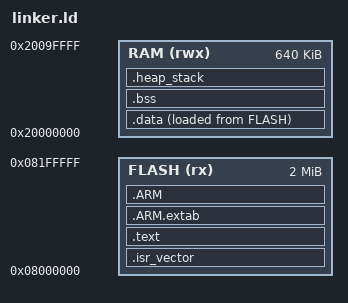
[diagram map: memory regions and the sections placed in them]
/*
 * linker.ld — STM32L4R5 linker script (rebarscope)
 * Author: jayis1
 * Copyright (C) 2026 jayis1. All rights reserved.
 * SPDX-License-Identifier: GPL-3.0
 */
MEMORY
{
    FLASH (rx) : ORIGIN = 0x08000000, LENGTH = 2048K
    RAM   (rwx) : ORIGIN = 0x20000000, LENGTH = 640K
}

_estack = ORIGIN(RAM) + LENGTH(RAM);

SECTIONS
{
    .isr_vector :
    {
        . = ALIGN(4);
        KEEP(*(.isr_vector))
        . = ALIGN(4);
    } > FLASH

    .text :
    {
        . = ALIGN(4);
        *(.text)
        *(.text*)
        *(.rodata)
        *(.rodata*)
        . = ALIGN(4);
        _etext = .;
    } > FLASH

    .ARM.extab : { *(.ARM.extab* .gnu.linkonce.armextab.*) } > FLASH
    .ARM : { __exidx_start = .; *(.ARM.exidx*) __exidx_end = .; } > FLASH

    _sidata = LOADADDR(.data);
    .data :
    {
        . = ALIGN(4);
        _sdata = .;
        *(.data)
        *(.data*)
        . = ALIGN(4);
        _edata = .;
    } > RAM AT> FLASH

    .bss :
    {
        . = ALIGN(4);
        _sbss = .;
        __bss_start__ = .;
        *(.bss)
        *(.bss*)
        *(COMMON)
        . = ALIGN(4);
        _ebss = .;
        __bss_end__ = .;
    } > RAM

    .heap_stack :
    {
        . = ALIGN(8);
        PROVIDE(end = .);
        PROVIDE(_end = .);
        . = . + 0x400;
        . = ALIGN(8);
    } > RAM

    _flash_end = ORIGIN(FLASH) + LENGTH(FLASH);
}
